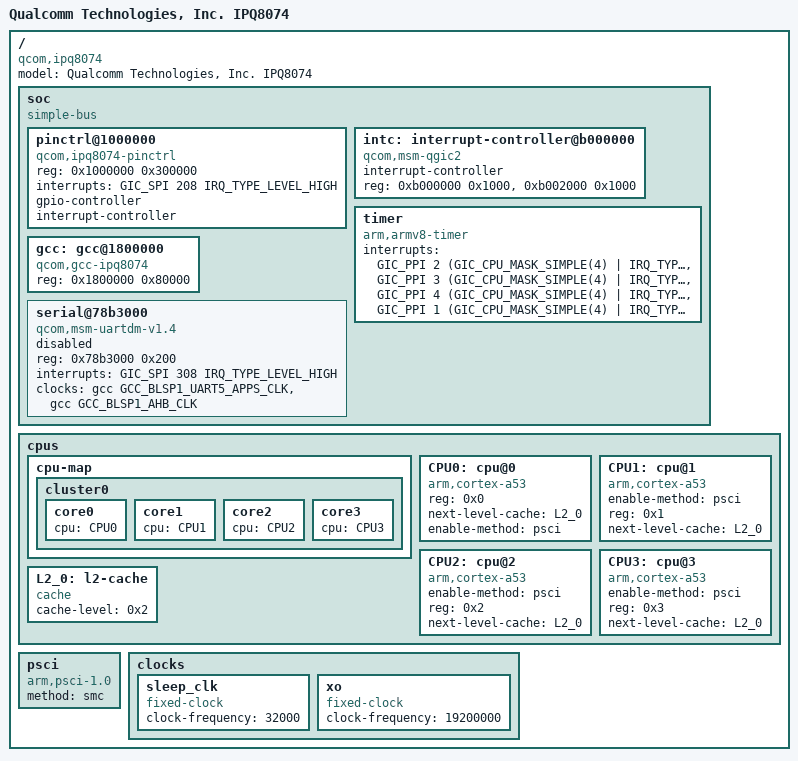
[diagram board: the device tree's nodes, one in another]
/*
 * Copyright (c) 2017, The Linux Foundation. All rights reserved.
 *
 * This program is free software; you can redistribute it and/or modify
 * it under the terms of the GNU General Public License version 2 and
 * only version 2 as published by the Free Software Foundation.
 *
 * This program is distributed in the hope that it will be useful,
 * but WITHOUT ANY WARRANTY; without even the implied warranty of
 * MERCHANTABILITY or FITNESS FOR A PARTICULAR PURPOSE.  See the
 * GNU General Public License for more details.
 */

#include <dt-bindings/interrupt-controller/arm-gic.h>
#include <dt-bindings/clock/qcom,gcc-ipq8074.h>

/ {
	model = "Qualcomm Technologies, Inc. IPQ8074";
	compatible = "qcom,ipq8074";

	soc: soc {
		#address-cells = <0x1>;
		#size-cells = <0x1>;
		ranges = <0 0 0 0xffffffff>;
		compatible = "simple-bus";

		pinctrl@1000000 {
			compatible = "qcom,ipq8074-pinctrl";
			reg = <0x1000000 0x300000>;
			interrupts = <GIC_SPI 208 IRQ_TYPE_LEVEL_HIGH>;
			gpio-controller;
			#gpio-cells = <0x2>;
			interrupt-controller;
			#interrupt-cells = <0x2>;
		};

		intc: interrupt-controller@b000000 {
			compatible = "qcom,msm-qgic2";
			interrupt-controller;
			#interrupt-cells = <0x3>;
			reg = <0xb000000 0x1000>,
			<0xb002000 0x1000>;
		};

		timer {
			compatible = "arm,armv8-timer";
			interrupts = <GIC_PPI 2 (GIC_CPU_MASK_SIMPLE(4) | IRQ_TYPE_LEVEL_LOW)>,
				     <GIC_PPI 3 (GIC_CPU_MASK_SIMPLE(4) | IRQ_TYPE_LEVEL_LOW)>,
				     <GIC_PPI 4 (GIC_CPU_MASK_SIMPLE(4) | IRQ_TYPE_LEVEL_LOW)>,
				     <GIC_PPI 1 (GIC_CPU_MASK_SIMPLE(4) | IRQ_TYPE_LEVEL_LOW)>;
		};

		gcc: gcc@1800000 {
			compatible = "qcom,gcc-ipq8074";
			reg = <0x1800000 0x80000>;
			#clock-cells = <0x1>;
			#reset-cells = <0x1>;
		};

		serial@78b3000 {
			compatible = "qcom,msm-uartdm-v1.4", "qcom,msm-uartdm";
			reg = <0x78b3000 0x200>;
			interrupts = <GIC_SPI 308 IRQ_TYPE_LEVEL_HIGH>;
			clocks = <&gcc GCC_BLSP1_UART5_APPS_CLK>,
				 <&gcc GCC_BLSP1_AHB_CLK>;
			clock-names = "core", "iface";
			status = "disabled";
		};
	};

	cpus {
		#address-cells = <0x1>;
		#size-cells = <0x0>;

		cpu-map {

			cluster0 {

				core0 {
					cpu = <&CPU0>;
				};

				core1 {
					cpu = <&CPU1>;
				};

				core2 {
					cpu = <&CPU2>;
				};

				core3 {
					cpu = <&CPU3>;
				};
			};
		};

		CPU0: cpu@0 {
			device_type = "cpu";
			compatible = "arm,cortex-a53", "arm,armv8";
			reg = <0x0>;
			next-level-cache = <&L2_0>;
			enable-method = "psci";
		};

		CPU1: cpu@1 {
			device_type = "cpu";
			compatible = "arm,cortex-a53", "arm,armv8";
			enable-method = "psci";
			reg = <0x1>;
			next-level-cache = <&L2_0>;
		};

		CPU2: cpu@2 {
			device_type = "cpu";
			compatible = "arm,cortex-a53", "arm,armv8";
			enable-method = "psci";
			reg = <0x2>;
			next-level-cache = <&L2_0>;
		};

		CPU3: cpu@3 {
			device_type = "cpu";
			compatible = "arm,cortex-a53", "arm,armv8";
			enable-method = "psci";
			reg = <0x3>;
			next-level-cache = <&L2_0>;
		};

		L2_0: l2-cache {
			compatible = "cache";
			cache-level = <0x2>;
		};
	};

	psci {
		compatible = "arm,psci-1.0";
		method = "smc";
	};

	clocks {
		sleep_clk: sleep_clk {
			compatible = "fixed-clock";
			clock-frequency = <32000>;
			#clock-cells = <0>;
		};

		xo: xo {
			compatible = "fixed-clock";
			clock-frequency = <19200000>;
			#clock-cells = <0>;
		};
	};
};
